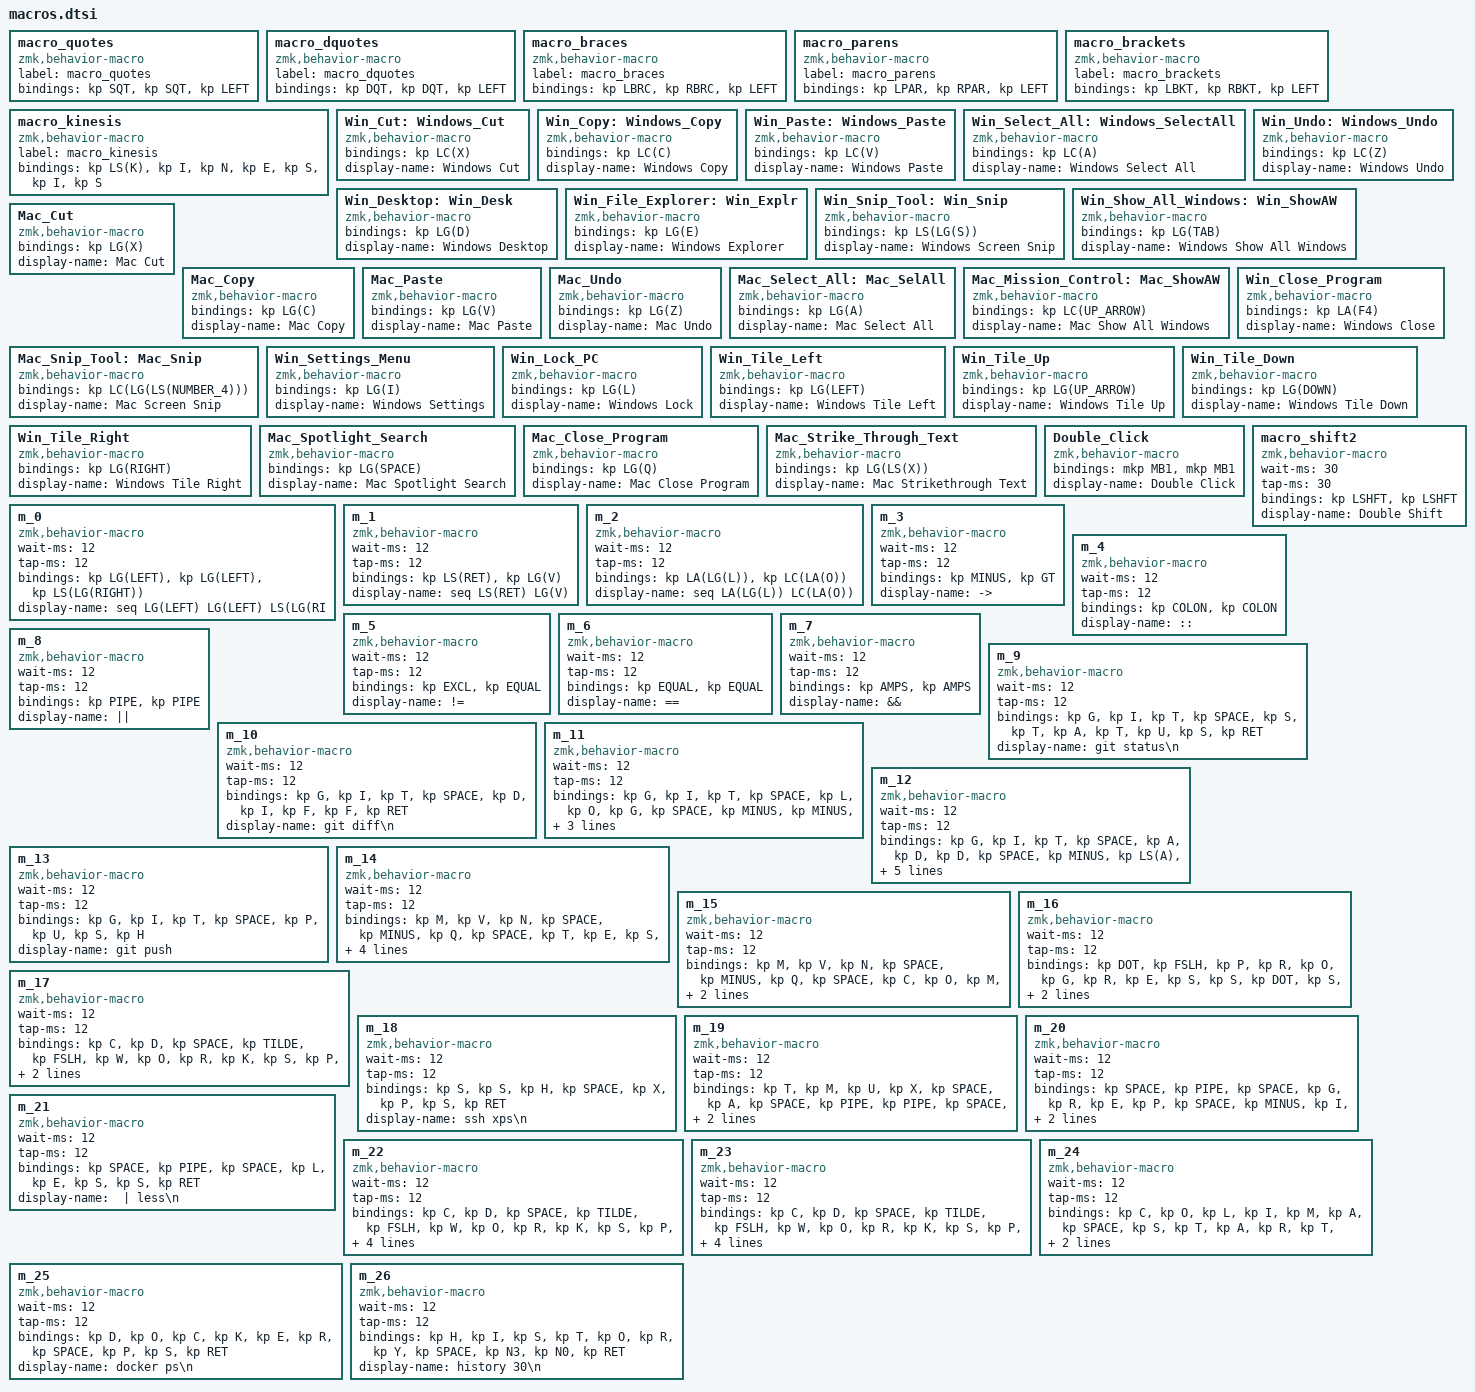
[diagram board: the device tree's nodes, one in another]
  macro_quotes: macro_quotes {
    compatible = "zmk,behavior-macro";
    label = "macro_quotes";
    #binding-cells = <0>;
    bindings = <&kp SQT>, <&kp SQT>, <&kp LEFT>;
  };
  macro_dquotes: macro_dquotes {
    compatible = "zmk,behavior-macro";
    label = "macro_dquotes";
    #binding-cells = <0>;
    bindings = <&kp DQT>, <&kp DQT>, <&kp LEFT>;
  };
  macro_braces: macro_braces {
    compatible = "zmk,behavior-macro";
    label = "macro_braces";
    #binding-cells = <0>;
    bindings = <&kp LBRC>, <&kp RBRC>, <&kp LEFT>;
  };
  macro_parens: macro_parens {
    compatible = "zmk,behavior-macro";
    label = "macro_parens";
    #binding-cells = <0>;
    bindings = <&kp LPAR>, <&kp RPAR>, <&kp LEFT>;
  };
  macro_brackets: macro_brackets {
    compatible = "zmk,behavior-macro";
    label = "macro_brackets";
    #binding-cells = <0>;
    bindings = <&kp LBKT>, <&kp RBKT>, <&kp LEFT>;
  };
  macro_kinesis: macro_kinesis {
    compatible = "zmk,behavior-macro";
    label = "macro_kinesis";
    #binding-cells = <0>;
    bindings = <&kp LS(K)>, <&kp I>, <&kp N>, <&kp E>, <&kp S>, <&kp I>, <&kp S>;
  };
  Win_Cut: Windows_Cut {
    compatible = "zmk,behavior-macro";
    #binding-cells = <0>;
    bindings = <&kp LC(X)>;
    display-name = "Windows Cut";
  };

  Win_Copy: Windows_Copy {
    compatible = "zmk,behavior-macro";
    #binding-cells = <0>;
    bindings = <&kp LC(C)>;
    display-name = "Windows Copy";
  };

  Win_Paste: Windows_Paste {
    compatible = "zmk,behavior-macro";
    #binding-cells = <0>;
    bindings = <&kp LC(V)>;
    display-name = "Windows Paste";
  };

  Win_Select_All: Windows_SelectAll {
      compatible = "zmk,behavior-macro";
      #binding-cells = <0>;
      bindings = <&kp LC(A)>;
      display-name = "Windows Select All";
  };

  Win_Undo: Windows_Undo {
    compatible = "zmk,behavior-macro";
    #binding-cells = <0>;
    bindings = <&kp LC(Z)>;
    display-name = "Windows Undo";
  };

  Win_Desktop: Win_Desk {
    compatible = "zmk,behavior-macro";
    #binding-cells = <0>;
    bindings = <&kp LG(D)>;
    display-name = "Windows Desktop";
  };

  Win_File_Explorer: Win_Explr {
    compatible = "zmk,behavior-macro";
    #binding-cells = <0>;
    bindings = <&kp LG(E)>;
    display-name = "Windows Explorer";
  };

  Win_Snip_Tool: Win_Snip {
    compatible = "zmk,behavior-macro";
    #binding-cells = <0>;
    bindings = <&kp LS(LG(S))>;
    display-name = "Windows Screen Snip";
  };

  Win_Show_All_Windows: Win_ShowAW {
    compatible = "zmk,behavior-macro";
    #binding-cells = <0>;
    bindings = <&kp LG(TAB)>;
    display-name = "Windows Show All Windows";
  };

  Mac_Cut: Mac_Cut {
    compatible = "zmk,behavior-macro";
    #binding-cells = <0>;
    bindings = <&kp LG(X)>;
    display-name = "Mac Cut";
  };

  Mac_Copy: Mac_Copy {
    compatible = "zmk,behavior-macro";
    #binding-cells = <0>;
    bindings = <&kp LG(C)>;
    display-name = "Mac Copy";
  };

  Mac_Paste: Mac_Paste {
    compatible = "zmk,behavior-macro";
    #binding-cells = <0>;
    bindings = <&kp LG(V)>;
    display-name = "Mac Paste";
  };

  Mac_Undo: Mac_Undo {
    compatible = "zmk,behavior-macro";
    #binding-cells = <0>;
    bindings = <&kp LG(Z)>;
    display-name = "Mac Undo";
  };

  Mac_Select_All: Mac_SelAll {
    compatible = "zmk,behavior-macro";
    #binding-cells = <0>;
    bindings = <&kp LG(A)>;
    display-name = "Mac Select All";
  };

  Mac_Mission_Control: Mac_ShowAW {
    compatible = "zmk,behavior-macro";
    #binding-cells = <0>;
    bindings = <&kp LC(UP_ARROW)>;
    display-name = "Mac Show All Windows";
  };

  Mac_Snip_Tool: Mac_Snip {
    compatible = "zmk,behavior-macro";
    #binding-cells = <0>;
    bindings = <&kp LC(LG(LS(NUMBER_4)))>;
    display-name = "Mac Screen Snip";
  };

  Win_Close_Program: Win_Close_Program {
    compatible = "zmk,behavior-macro";
    #binding-cells = <0>;
    bindings = <&kp LA(F4)>;
    display-name = "Windows Close";
  };

  Win_Settings_Menu: Win_Settings_Menu {
    compatible = "zmk,behavior-macro";
    #binding-cells = <0>;
    bindings = <&kp LG(I)>;
    display-name = "Windows Settings";
  };

  Win_Lock_PC: Win_Lock_PC {
    compatible = "zmk,behavior-macro";
    #binding-cells = <0>;
    bindings = <&kp LG(L)>;
    display-name = "Windows Lock";
  };

  Win_Tile_Left: Win_Tile_Left {
    compatible = "zmk,behavior-macro";
    #binding-cells = <0>;
    bindings = <&kp LG(LEFT)>;
    display-name = "Windows Tile Left";
  };

  Win_Tile_Up: Win_Tile_Up {
    compatible = "zmk,behavior-macro";
    #binding-cells = <0>;
    bindings = <&kp LG(UP_ARROW)>;
    display-name = "Windows Tile Up";
  };

  Win_Tile_Down: Win_Tile_Down {
    compatible = "zmk,behavior-macro";
    #binding-cells = <0>;
    bindings = <&kp LG(DOWN)>;
    display-name = "Windows Tile Down";
  };

  Win_Tile_Right: Win_Tile_Right {
    compatible = "zmk,behavior-macro";
    #binding-cells = <0>;
    bindings = <&kp LG(RIGHT)>;
    display-name = "Windows Tile Right";
  };

  Mac_Spotlight_Search: Mac_Spotlight_Search {
    compatible = "zmk,behavior-macro";
    #binding-cells = <0>;
    bindings = <&kp LG(SPACE)>;
    display-name = "Mac Spotlight Search";
  };

  Mac_Close_Program: Mac_Close_Program {
    compatible = "zmk,behavior-macro";
    #binding-cells = <0>;
    bindings = <&kp LG(Q)>;
    display-name = "Mac Close Program";
  };

  Mac_Strike_Through_Text: Mac_Strike_Through_Text {
    compatible = "zmk,behavior-macro";
    #binding-cells = <0>;
    bindings = <&kp LG(LS(X))>;
    display-name = "Mac Strikethrough Text";
  };

  Double_Click: Double_Click {
    compatible = "zmk,behavior-macro";
    #binding-cells = <0>;
    bindings = <&mkp MB1 &mkp MB1>;
    display-name = "Double Click";
  };

  // ---- keyboard-flow macros (generated by layout.py) ----
  macro_shift2: macro_shift2 {
    compatible = "zmk,behavior-macro";
    #binding-cells = <0>;
    wait-ms = <30>;
    tap-ms = <30>;
    bindings = <&kp LSHFT>, <&kp LSHFT>;
    display-name = "Double Shift";
  };
  m_0: m_0 {
    compatible = "zmk,behavior-macro";
    #binding-cells = <0>;
    wait-ms = <12>;
    tap-ms = <12>;
    bindings = <&kp LG(LEFT)>, <&kp LG(LEFT)>, <&kp LS(LG(RIGHT))>;
    display-name = "seq LG(LEFT) LG(LEFT) LS(LG(RI";
  };
  m_1: m_1 {
    compatible = "zmk,behavior-macro";
    #binding-cells = <0>;
    wait-ms = <12>;
    tap-ms = <12>;
    bindings = <&kp LS(RET)>, <&kp LG(V)>;
    display-name = "seq LS(RET) LG(V)";
  };
  m_2: m_2 {
    compatible = "zmk,behavior-macro";
    #binding-cells = <0>;
    wait-ms = <12>;
    tap-ms = <12>;
    bindings = <&kp LA(LG(L))>, <&kp LC(LA(O))>;
    display-name = "seq LA(LG(L)) LC(LA(O))";
  };
  m_3: m_3 {
    compatible = "zmk,behavior-macro";
    #binding-cells = <0>;
    wait-ms = <12>;
    tap-ms = <12>;
    bindings = <&kp MINUS>, <&kp GT>;
    display-name = "->";
  };
  m_4: m_4 {
    compatible = "zmk,behavior-macro";
    #binding-cells = <0>;
    wait-ms = <12>;
    tap-ms = <12>;
    bindings = <&kp COLON>, <&kp COLON>;
    display-name = "::";
  };
  m_5: m_5 {
    compatible = "zmk,behavior-macro";
    #binding-cells = <0>;
    wait-ms = <12>;
    tap-ms = <12>;
    bindings = <&kp EXCL>, <&kp EQUAL>;
    display-name = "!=";
  };
  m_6: m_6 {
    compatible = "zmk,behavior-macro";
    #binding-cells = <0>;
    wait-ms = <12>;
    tap-ms = <12>;
    bindings = <&kp EQUAL>, <&kp EQUAL>;
    display-name = "==";
  };
  m_7: m_7 {
    compatible = "zmk,behavior-macro";
    #binding-cells = <0>;
    wait-ms = <12>;
    tap-ms = <12>;
    bindings = <&kp AMPS>, <&kp AMPS>;
    display-name = "&&";
  };
  m_8: m_8 {
    compatible = "zmk,behavior-macro";
    #binding-cells = <0>;
    wait-ms = <12>;
    tap-ms = <12>;
    bindings = <&kp PIPE>, <&kp PIPE>;
    display-name = "||";
  };
  m_9: m_9 {
    compatible = "zmk,behavior-macro";
    #binding-cells = <0>;
    wait-ms = <12>;
    tap-ms = <12>;
    bindings = <&kp G>, <&kp I>, <&kp T>, <&kp SPACE>, <&kp S>, <&kp T>, <&kp A>, <&kp T>, <&kp U>, <&kp S>, <&kp RET>;
    display-name = "git status\n";
  };
  m_10: m_10 {
    compatible = "zmk,behavior-macro";
    #binding-cells = <0>;
    wait-ms = <12>;
    tap-ms = <12>;
    bindings = <&kp G>, <&kp I>, <&kp T>, <&kp SPACE>, <&kp D>, <&kp I>, <&kp F>, <&kp F>, <&kp RET>;
    display-name = "git diff\n";
  };
  m_11: m_11 {
    compatible = "zmk,behavior-macro";
    #binding-cells = <0>;
    wait-ms = <12>;
    tap-ms = <12>;
    bindings = <&kp G>, <&kp I>, <&kp T>, <&kp SPACE>, <&kp L>, <&kp O>, <&kp G>, <&kp SPACE>, <&kp MINUS>, <&kp MINUS>, <&kp O>, <&kp N>, <&kp E>, <&kp L>, <&kp I>, <&kp N>, <&kp E>, <&kp SPACE>, <&kp MINUS>, <&kp N1>, <&kp N5>, <&kp RET>;
    display-name = "git log --oneline -15\n";
  };
  m_12: m_12 {
    compatible = "zmk,behavior-macro";
    #binding-cells = <0>;
    wait-ms = <12>;
    tap-ms = <12>;
    bindings = <&kp G>, <&kp I>, <&kp T>, <&kp SPACE>, <&kp A>, <&kp D>, <&kp D>, <&kp SPACE>, <&kp MINUS>, <&kp LS(A)>, <&kp SPACE>, <&kp AMPS>, <&kp AMPS>, <&kp SPACE>, <&kp G>, <&kp I>, <&kp T>, <&kp SPACE>, <&kp C>, <&kp O>, <&kp M>, <&kp M>, <&kp I>, <&kp T>, <&kp SPACE>, <&kp MINUS>, <&kp M>, <&kp SPACE>, <&kp DQT>, <&kp DQT>, <&kp LEFT>;
    display-name = "git add -A && git commit -m {L";
  };
  m_13: m_13 {
    compatible = "zmk,behavior-macro";
    #binding-cells = <0>;
    wait-ms = <12>;
    tap-ms = <12>;
    bindings = <&kp G>, <&kp I>, <&kp T>, <&kp SPACE>, <&kp P>, <&kp U>, <&kp S>, <&kp H>;
    display-name = "git push";
  };
  m_14: m_14 {
    compatible = "zmk,behavior-macro";
    #binding-cells = <0>;
    wait-ms = <12>;
    tap-ms = <12>;
    bindings = <&kp M>, <&kp V>, <&kp N>, <&kp SPACE>, <&kp MINUS>, <&kp Q>, <&kp SPACE>, <&kp T>, <&kp E>, <&kp S>, <&kp T>, <&kp SPACE>, <&kp MINUS>, <&kp LS(D)>, <&kp T>, <&kp E>, <&kp S>, <&kp T>, <&kp EQUAL>, <&kp SQT>, <&kp SQT>, <&kp LEFT>;
    display-name = "mvn -q test -Dtest=''{LEFT}";
  };
  m_15: m_15 {
    compatible = "zmk,behavior-macro";
    #binding-cells = <0>;
    wait-ms = <12>;
    tap-ms = <12>;
    bindings = <&kp M>, <&kp V>, <&kp N>, <&kp SPACE>, <&kp MINUS>, <&kp Q>, <&kp SPACE>, <&kp C>, <&kp O>, <&kp M>, <&kp P>, <&kp I>, <&kp L>, <&kp E>, <&kp RET>;
    display-name = "mvn -q compile\n";
  };
  m_16: m_16 {
    compatible = "zmk,behavior-macro";
    #binding-cells = <0>;
    wait-ms = <12>;
    tap-ms = <12>;
    bindings = <&kp DOT>, <&kp FSLH>, <&kp P>, <&kp R>, <&kp O>, <&kp G>, <&kp R>, <&kp E>, <&kp S>, <&kp S>, <&kp DOT>, <&kp S>, <&kp H>, <&kp SPACE>;
    display-name = "./progress.sh ";
  };
  m_17: m_17 {
    compatible = "zmk,behavior-macro";
    #binding-cells = <0>;
    wait-ms = <12>;
    tap-ms = <12>;
    bindings = <&kp C>, <&kp D>, <&kp SPACE>, <&kp TILDE>, <&kp FSLH>, <&kp W>, <&kp O>, <&kp R>, <&kp K>, <&kp S>, <&kp P>, <&kp A>, <&kp C>, <&kp E>, <&kp FSLH>;
    display-name = "cd ~/workspace/";
  };
  m_18: m_18 {
    compatible = "zmk,behavior-macro";
    #binding-cells = <0>;
    wait-ms = <12>;
    tap-ms = <12>;
    bindings = <&kp S>, <&kp S>, <&kp H>, <&kp SPACE>, <&kp X>, <&kp P>, <&kp S>, <&kp RET>;
    display-name = "ssh xps\n";
  };
  m_19: m_19 {
    compatible = "zmk,behavior-macro";
    #binding-cells = <0>;
    wait-ms = <12>;
    tap-ms = <12>;
    bindings = <&kp T>, <&kp M>, <&kp U>, <&kp X>, <&kp SPACE>, <&kp A>, <&kp SPACE>, <&kp PIPE>, <&kp PIPE>, <&kp SPACE>, <&kp T>, <&kp M>, <&kp U>, <&kp X>, <&kp RET>;
    display-name = "tmux a || tmux\n";
  };
  m_20: m_20 {
    compatible = "zmk,behavior-macro";
    #binding-cells = <0>;
    wait-ms = <12>;
    tap-ms = <12>;
    bindings = <&kp SPACE>, <&kp PIPE>, <&kp SPACE>, <&kp G>, <&kp R>, <&kp E>, <&kp P>, <&kp SPACE>, <&kp MINUS>, <&kp I>, <&kp SPACE>;
    display-name = " | grep -i ";
  };
  m_21: m_21 {
    compatible = "zmk,behavior-macro";
    #binding-cells = <0>;
    wait-ms = <12>;
    tap-ms = <12>;
    bindings = <&kp SPACE>, <&kp PIPE>, <&kp SPACE>, <&kp L>, <&kp E>, <&kp S>, <&kp S>, <&kp RET>;
    display-name = " | less\n";
  };
  m_22: m_22 {
    compatible = "zmk,behavior-macro";
    #binding-cells = <0>;
    wait-ms = <12>;
    tap-ms = <12>;
    bindings = <&kp C>, <&kp D>, <&kp SPACE>, <&kp TILDE>, <&kp FSLH>, <&kp W>, <&kp O>, <&kp R>, <&kp K>, <&kp S>, <&kp P>, <&kp A>, <&kp C>, <&kp E>, <&kp FSLH>, <&kp J>, <&kp A>, <&kp V>, <&kp A>, <&kp MINUS>, <&kp D>, <&kp R>, <&kp I>, <&kp L>, <&kp L>, <&kp I>, <&kp N>, <&kp G>, <&kp RET>;
    display-name = "cd ~/workspace/java-drilling\n";
  };
  m_23: m_23 {
    compatible = "zmk,behavior-macro";
    #binding-cells = <0>;
    wait-ms = <12>;
    tap-ms = <12>;
    bindings = <&kp C>, <&kp D>, <&kp SPACE>, <&kp TILDE>, <&kp FSLH>, <&kp W>, <&kp O>, <&kp R>, <&kp K>, <&kp S>, <&kp P>, <&kp A>, <&kp C>, <&kp E>, <&kp FSLH>, <&kp A>, <&kp X>, <&kp O>, <&kp N>, <&kp MINUS>, <&kp B>, <&kp A>, <&kp N>, <&kp K>, <&kp RET>;
    display-name = "cd ~/workspace/axon-bank\n";
  };
  m_24: m_24 {
    compatible = "zmk,behavior-macro";
    #binding-cells = <0>;
    wait-ms = <12>;
    tap-ms = <12>;
    bindings = <&kp C>, <&kp O>, <&kp L>, <&kp I>, <&kp M>, <&kp A>, <&kp SPACE>, <&kp S>, <&kp T>, <&kp A>, <&kp R>, <&kp T>, <&kp RET>;
    display-name = "colima start\n";
  };
  m_25: m_25 {
    compatible = "zmk,behavior-macro";
    #binding-cells = <0>;
    wait-ms = <12>;
    tap-ms = <12>;
    bindings = <&kp D>, <&kp O>, <&kp C>, <&kp K>, <&kp E>, <&kp R>, <&kp SPACE>, <&kp P>, <&kp S>, <&kp RET>;
    display-name = "docker ps\n";
  };
  m_26: m_26 {
    compatible = "zmk,behavior-macro";
    #binding-cells = <0>;
    wait-ms = <12>;
    tap-ms = <12>;
    bindings = <&kp H>, <&kp I>, <&kp S>, <&kp T>, <&kp O>, <&kp R>, <&kp Y>, <&kp SPACE>, <&kp N3>, <&kp N0>, <&kp RET>;
    display-name = "history 30\n";
  };
